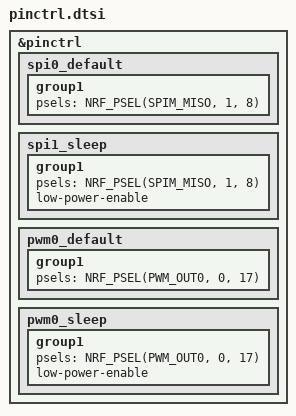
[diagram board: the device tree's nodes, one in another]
/*
 * Copyright (c) 2022 The ZMK Contributors
 * SPDX-License-Identifier: MIT
 */

&pinctrl {
	spi0_default: spi0_default {
		group1 {
			psels = <NRF_PSEL(SPIM_MOSI, 0, 20)>;
			psels = <NRF_PSEL(SPIM_SCK, 0, 17)>;
			psels = <NRF_PSEL(SPIM_MISO, 1, 8)>;
		};
	};
	spi1_sleep: spi1_sleep {
		group1 {
			psels = <NRF_PSEL(SPIM_MOSI, 0, 20)>;
			psels = <NRF_PSEL(SPIM_SCK, 0, 17)>;
			psels = <NRF_PSEL(SPIM_MISO, 1, 8)>;
		low-power-enable;
		};
	};
	pwm0_default: pwm0_default {
		group1 {
			psels = <NRF_PSEL(PWM_OUT0, 0, 17)>;
		};
	};
	pwm0_sleep: pwm0_sleep {
		group1 {
			psels = <NRF_PSEL(PWM_OUT0, 0, 17)>;
		low-power-enable;
		};
	};
};
